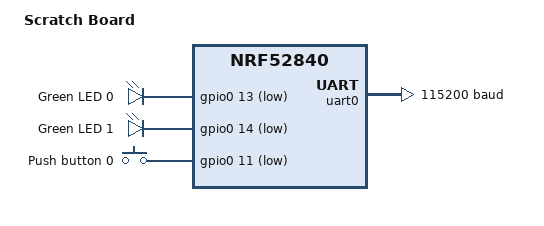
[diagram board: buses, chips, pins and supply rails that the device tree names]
/*
 * Copyright (c) 2024 Swaroop
 * SPDX-License-Identifier: Apache-2.0
 *
 * Scratch Board - From Scratch method
 * Based on nRF52840 SoC
 */

/dts-v1/;
#include <nordic/nrf52840_qiaa.dtsi>
#include <nordic/nrf52840_partition.dtsi>
#include "scratch_board-pinctrl.dtsi"
#include <zephyr/dt-bindings/input/input-event-codes.h>

/ {
	model = "Scratch Board";
	compatible = "swaroop,scratch-board";

	chosen {
		zephyr,console = &uart0;
		zephyr,shell-uart = &uart0;
		zephyr,sram = &sram0;
		zephyr,flash = &flash0;
		zephyr,code-partition = &slot0_partition;
	};

	leds {
		compatible = "gpio-leds";
		led0: led_0 {
			gpios = <&gpio0 13 GPIO_ACTIVE_LOW>;
			label = "Green LED 0";
		};
		led1: led_1 {
			gpios = <&gpio0 14 GPIO_ACTIVE_LOW>;
			label = "Green LED 1";
		};
	};

	buttons {
		compatible = "gpio-keys";
		button0: button_0 {
			gpios = <&gpio0 11 (GPIO_PULL_UP | GPIO_ACTIVE_LOW)>;
			label = "Push button 0";
			zephyr,code = <INPUT_KEY_0>;
		};
	};

	aliases {
		led0 = &led0;
		led1 = &led1;
		sw0 = &button0;
		watchdog0 = &wdt0;
	};
};

&uicr {
	gpio-as-nreset;
};

&gpiote {
	status = "okay";
};

&gpio0 {
	status = "okay";
};

&gpio1 {
	status = "okay";
};

&uart0 {
	compatible = "nordic,nrf-uarte";
	status = "okay";
	current-speed = <115200>;
	pinctrl-0 = <&uart0_default>;
	pinctrl-1 = <&uart0_sleep>;
	pinctrl-names = "default", "sleep";
};
